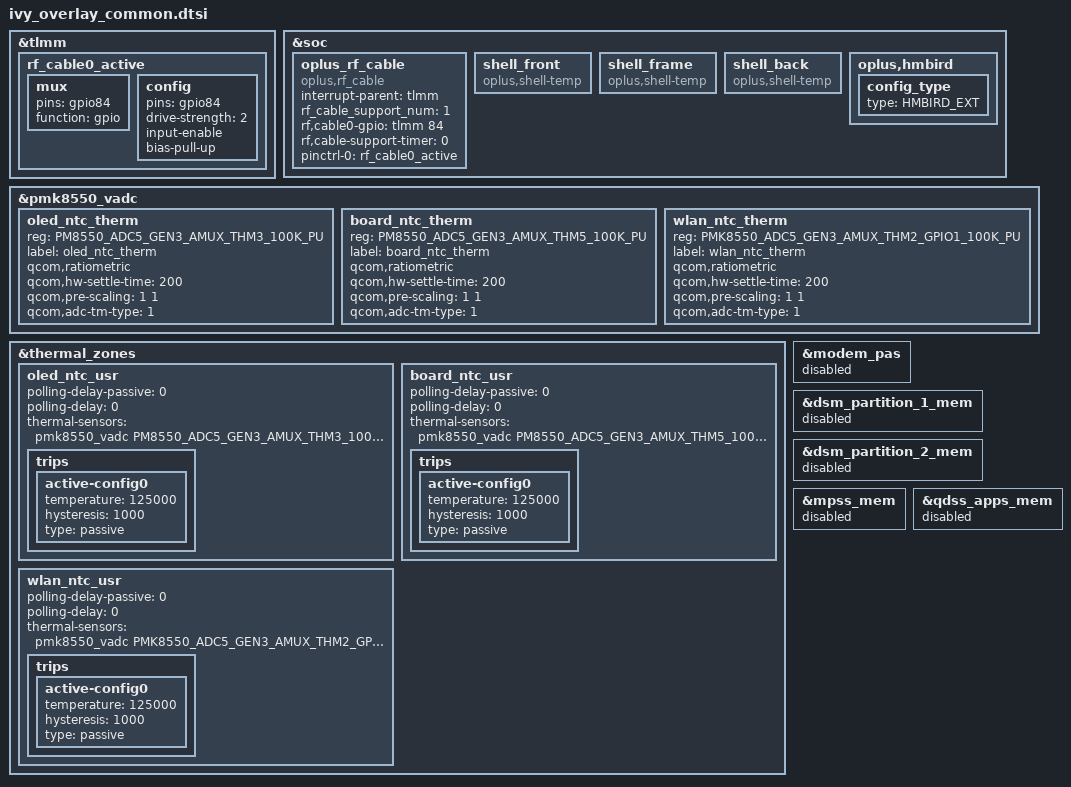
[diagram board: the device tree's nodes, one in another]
&tlmm {
    //#ifdef OPLUS_FEATURE_RF_CABLE_DETECT
    rf_cable0_active: rf_cable0_active {
        mux {
            pins = "gpio84";
            function = "gpio";
        };
        config {
            pins = "gpio84";
            drive-strength = <2>;
            input-enable;
            bias-pull-up;
        };
    };
    //#endif /* OPLUS_FEATURE_RF_CABLE_DETECT */
};
&soc {
        //#ifdef OPLUS_FEATURE_RF_CABLE_DETECT
        oplus_rf_cable {
                compatible = "oplus,rf_cable";
                interrupt-parent = <&tlmm>;
                rf_cable_support_num = <1>;
                rf,cable0-gpio = <&tlmm 84 0>;
                rf,cable-support-timer = <0>;
                pinctrl-names = "rf_cable_active";
                pinctrl-0 = <&rf_cable0_active>;
        };
        //#endif /* OPLUS_FEATURE_RF_CABLE_DETECT */

        //#ifdef OPLUS_FEATURE_THERMAL_HORAE
        shell_front {
                compatible = "oplus,shell-temp";
        };

        shell_frame {
                compatible = "oplus,shell-temp";
        };

        shell_back {
                compatible = "oplus,shell-temp";
        };
        //#endif /* OPLUS_FEATURE_THERMAL_HORAE */

        //#ifdef CONFIG_HMBIRD_SCHED
        oplus,hmbird {
                config_type {
                        type = "HMBIRD_EXT";
                };
        };
        //#endif /* CONFIG_HMBIRD_SCHED */
};


&pmk8550_vadc {
    oled_ntc_therm {
        reg = <PM8550_ADC5_GEN3_AMUX_THM3_100K_PU>;
        label = "oled_ntc_therm";
        qcom,ratiometric;
        qcom,hw-settle-time = <200>;
        qcom,pre-scaling = <1 1>;
        qcom,adc-tm-type = <1>;
    };

    board_ntc_therm {
        reg = <PM8550_ADC5_GEN3_AMUX_THM5_100K_PU>;
        label = "board_ntc_therm";
        qcom,ratiometric;
        qcom,hw-settle-time = <200>;
        qcom,pre-scaling = <1 1>;
        qcom,adc-tm-type = <1>;
    };

    wlan_ntc_therm {
        reg = <PMK8550_ADC5_GEN3_AMUX_THM2_GPIO1_100K_PU>;
        label = "wlan_ntc_therm";
        qcom,ratiometric;
        qcom,hw-settle-time = <200>;
        qcom,pre-scaling = <1 1>;
        qcom,adc-tm-type = <1>;
    };

};

&thermal_zones {
    oled_ntc_usr {
        polling-delay-passive = <0>;
        polling-delay = <0>;
        thermal-sensors = <&pmk8550_vadc PM8550_ADC5_GEN3_AMUX_THM3_100K_PU>;
        trips {
            active-config0 {
                temperature = <125000>;
                hysteresis = <1000>;
                type = "passive";
            };
        };
    };

    board_ntc_usr {
        polling-delay-passive = <0>;
        polling-delay = <0>;
        thermal-sensors = <&pmk8550_vadc PM8550_ADC5_GEN3_AMUX_THM5_100K_PU>;
        trips {
            active-config0 {
                temperature = <125000>;
                hysteresis = <1000>;
                type = "passive";
            };
        };
    };

    wlan_ntc_usr {
        polling-delay-passive = <0>;
        polling-delay = <0>;
        thermal-sensors = <&pmk8550_vadc PMK8550_ADC5_GEN3_AMUX_THM2_GPIO1_100K_PU>;
        trips {
            active-config0 {
                temperature = <125000>;
                hysteresis = <1000>;
                type = "passive";
            };
        };
    };

};

&modem_pas {
    status = "no";
};
&dsm_partition_1_mem {
    status = "disabled";
};
&dsm_partition_2_mem{
    status = "disabled";
};
&mpss_mem{
    status = "disabled";
};
&qdss_apps_mem {
    status = "disabled";
};
